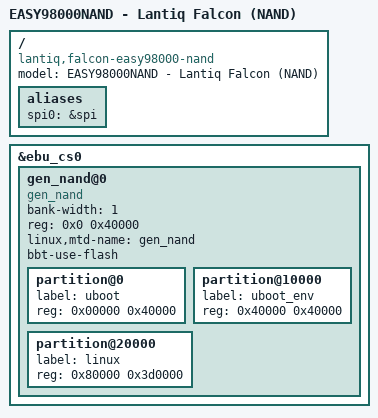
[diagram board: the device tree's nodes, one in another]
/dts-v1/;

#include "falcon.dtsi"
#include "EASY98000-base.dtsi"

/ {
	model = "EASY98000NAND - Lantiq Falcon (NAND)";
	compatible = "lantiq,falcon-easy98000-nand", "lantiq,falcon-easy98000", "lantiq,falcon";

	aliases {
		spi0 = &spi;
	};
};

&ebu_cs0 {
	gen_nand@0 {
		compatible = "gen_nand", "lantiq,nand-falcon";
		bank-width = <1>;
		reg = <0x0 0x40000>;
		#address-cells = <1>;
		#size-cells = <1>;
		linux,mtd-name = "gen_nand";
		bbt-use-flash;

		partition@0 {
			label = "uboot";
			reg = <0x00000 0x40000>;
		};

		partition@10000 {
			label = "uboot_env";
			reg = <0x40000 0x40000>;
		};

		partition@20000 {
			label = "linux";
			reg = <0x80000 0x3d0000>;
		};
	};
};
